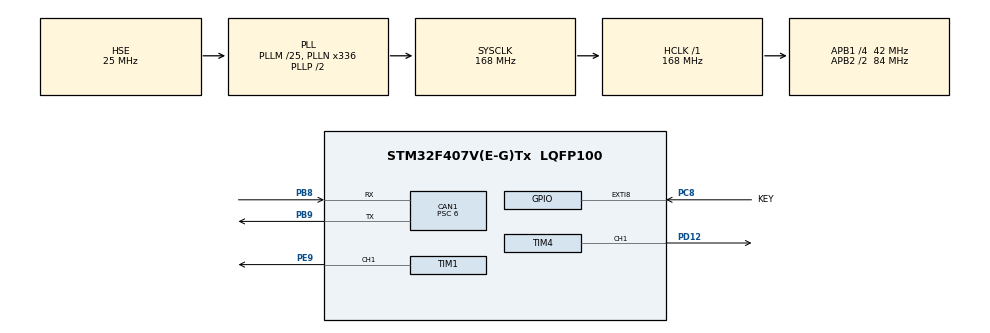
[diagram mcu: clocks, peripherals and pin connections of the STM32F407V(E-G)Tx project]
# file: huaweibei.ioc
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CAN1.BS1=CAN_BS1_3TQ
CAN1.BS2=CAN_BS2_3TQ
CAN1.CalculateTimeQuantum=142.85714285714286
CAN1.Prescaler=6
CAN1.TXFP=ENABLE
Mcu.Family=STM32F4
Mcu.Name=STM32F407V(E-G)Tx
Mcu.Package=LQFP100
NVIC.CAN1_RX0_IRQn=true\:1\:0\:true\:false\:true\:true\:true
NVIC.EXTI9_5_IRQn=true\:0\:0\:false\:false\:true\:true\:true
NVIC.PriorityGroup=NVIC_PRIORITYGROUP_4
NVIC.TIM2_IRQn=true\:1\:0\:true\:false\:true\:true\:true
NVIC.TIM3_IRQn=true\:2\:0\:true\:false\:true\:true\:true
PA13.Mode=Serial_Wire
PA13.Signal=SYS_JTMS-SWDIO
PA14.Mode=Serial_Wire
PA14.Signal=SYS_JTCK-SWCLK
PB8.Mode=Master
PB8.Signal=CAN1_RX
PB9.Mode=Master
PB9.Signal=CAN1_TX
PC8.GPIO_Label=KEY
PC8.GPIO_ModeDefaultEXTI=GPIO_MODE_IT_FALLING
PC8.GPIO_PuPd=GPIO_PULLUP
PC8.Signal=GPXTI8
PD12.Signal=S_TIM4_CH1
PE9.Signal=S_TIM1_CH1
PH0-OSC_IN.Mode=HSE-External-Oscillator
PH0-OSC_IN.Signal=RCC_OSC_IN
PH1-OSC_OUT.Mode=HSE-External-Oscillator
PH1-OSC_OUT.Signal=RCC_OSC_OUT
ProjectManager.HeapSize=0x200
ProjectManager.StackSize=0x400
ProjectManager.TargetToolchain=MDK-ARM V5
RCC.48MHZClocksFreq_Value=48000000
RCC.AHBFreq_Value=168000000
RCC.APB1CLKDivider=RCC_HCLK_DIV4
RCC.APB1Freq_Value=42000000
RCC.APB1TimFreq_Value=84000000
RCC.APB2CLKDivider=RCC_HCLK_DIV2
RCC.APB2Freq_Value=84000000
RCC.APB2TimFreq_Value=168000000
RCC.CortexFreq_Value=168000000
RCC.HCLKFreq_Value=168000000
RCC.HSE_VALUE=25000000
RCC.HSI_VALUE=16000000
RCC.LSE_VALUE=32768
RCC.PLLM=25
RCC.PLLN=336
RCC.PLLQ=7
RCC.PLLSourceVirtual=RCC_PLLSOURCE_HSE
RCC.SYSCLKFreq_VALUE=168000000
RCC.SYSCLKSource=RCC_SYSCLKSOURCE_PLLCLK
RCC.VCOOutputFreq_Value=336000000
SH.S_TIM1_CH1.0=TIM1_CH1,PWM Generation1 CH1
SH.S_TIM4_CH1.0=TIM4_CH1,PWM Generation1 CH1
TIM1.AutoReloadPreload=TIM_AUTORELOAD_PRELOAD_ENABLE
TIM1.Channel-PWM\ Generation1\ CH1=TIM_CHANNEL_1
TIM1.Period=19999
TIM1.Prescaler=167
TIM2.AutoReloadPreload=TIM_AUTORELOAD_PRELOAD_ENABLE
TIM2.Period=1999
TIM2.Prescaler=83
TIM3.AutoReloadPreload=TIM_AUTORELOAD_PRELOAD_ENABLE
TIM3.Period=4999
TIM3.Prescaler=8399
TIM4.AutoReloadPreload=TIM_AUTORELOAD_PRELOAD_ENABLE
TIM4.Channel-PWM\ Generation1\ CH1=TIM_CHANNEL_1
TIM4.Period=20000
TIM4.Prescaler=84
VP_RNG_VS_RNG.Mode=RNG_Activate
VP_TIM1_VS_ClockSourceINT.Mode=Internal
VP_TIM2_VS_ClockSourceINT.Mode=Internal
VP_TIM3_VS_ClockSourceINT.Mode=Internal
VP_TIM4_VS_ClockSourceINT.Mode=Internal
board=custom

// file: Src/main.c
/* USER CODE BEGIN Header */
/**
  ******************************************************************************
  * @file           : main.c
  * @brief          : Main program body
  ******************************************************************************
  * @attention
  *
  * <h2><center>&copy; Copyright (c) 2020 STMicroelectronics.
  * All rights reserved.</center></h2>
  *
  * This software component is licensed by ST under BSD 3-Clause license,
  * the "License"; You may not use this file except in compliance with the
  * License. You may obtain a copy of the License at:
  *                        opensource.org/licenses/BSD-3-Clause
  *
  ******************************************************************************
  */
/* USER CODE END Header */
#include "main.h"
#include "can.h"
#include "rng.h"
#include "tim.h"
#include "gpio.h"

/* USER CODE BEGIN Includes */
#include "CANDrive.h"
#include "PID.h"
#include "Motor.h"
/* USER CODE END Includes */

/* USER CODE BEGIN PV */
uint8_t mode_flag = 0;
/* USER CODE END PV */

void SystemClock_Config(void);

int main(void)
{

  /* MCU Configuration--------------------------------------------------------*/

  /* Reset of all peripherals, Initializes the Flash interface and the Systick. */
  HAL_Init();

  /* Configure the system clock */
  SystemClock_Config();

  /* Initialize all configured peripherals */
  MX_GPIO_Init();
  MX_CAN1_Init();
  MX_TIM2_Init();
  MX_TIM3_Init();
  MX_TIM4_Init();
  MX_TIM1_Init();
  MX_RNG_Init();
  /* USER CODE BEGIN 2 */
	CanFilter_Init(&hcan1);
	HAL_CAN_Start(&hcan1);
	HAL_CAN_ActivateNotification(&hcan1, CAN_IT_RX_FIFO0_MSG_PENDING);

	HAL_NVIC_EnableIRQ(EXTI9_5_IRQn);

	HAL_TIM_Base_Start_IT(&htim2);
	HAL_TIM_Base_Start_IT(&htim3);
	HAL_TIM_PWM_Start(&htim4,TIM_CHANNEL_1);
//	__HAL_TIM_SetCompare(&htim4, TIM_CHANNEL_1, 19000);						//归中
  /* USER CODE END 2 */

  /* Infinite loop */
  while (1)
  {

  }
}

void SystemClock_Config(void)
{
  RCC_OscInitTypeDef RCC_OscInitStruct = {0};
  RCC_ClkInitTypeDef RCC_ClkInitStruct = {0};

  /** Configure the main internal regulator output voltage
  */
  __HAL_RCC_PWR_CLK_ENABLE();
  __HAL_PWR_VOLTAGESCALING_CONFIG(PWR_REGULATOR_VOLTAGE_SCALE1);
  /** Initializes the RCC Oscillators according to the specified parameters
  * in the RCC_OscInitTypeDef structure.
  */
  RCC_OscInitStruct.OscillatorType = RCC_OSCILLATORTYPE_HSE;
  RCC_OscInitStruct.HSEState = RCC_HSE_ON;
  RCC_OscInitStruct.PLL.PLLState = RCC_PLL_ON;
  RCC_OscInitStruct.PLL.PLLSource = RCC_PLLSOURCE_HSE;
  RCC_OscInitStruct.PLL.PLLM = 25;
  RCC_OscInitStruct.PLL.PLLN = 336;
  RCC_OscInitStruct.PLL.PLLP = RCC_PLLP_DIV2;
  RCC_OscInitStruct.PLL.PLLQ = 7;
  if (HAL_RCC_OscConfig(&RCC_OscInitStruct) != HAL_OK)
  {
    Error_Handler();
  }
  /** Initializes the CPU, AHB and APB buses clocks
  */
  RCC_ClkInitStruct.ClockType = RCC_CLOCKTYPE_HCLK|RCC_CLOCKTYPE_SYSCLK
                              |RCC_CLOCKTYPE_PCLK1|RCC_CLOCKTYPE_PCLK2;
  RCC_ClkInitStruct.SYSCLKSource = RCC_SYSCLKSOURCE_PLLCLK;
  RCC_ClkInitStruct.AHBCLKDivider = RCC_SYSCLK_DIV1;
  RCC_ClkInitStruct.APB1CLKDivider = RCC_HCLK_DIV4;
  RCC_ClkInitStruct.APB2CLKDivider = RCC_HCLK_DIV2;

  if (HAL_RCC_ClockConfig(&RCC_ClkInitStruct, FLASH_LATENCY_5) != HAL_OK)
  {
    Error_Handler();
  }
}

void Error_Handler(void)
{
}

/************************ (C) COPYRIGHT STMicroelectronics *****END OF FILE****/
